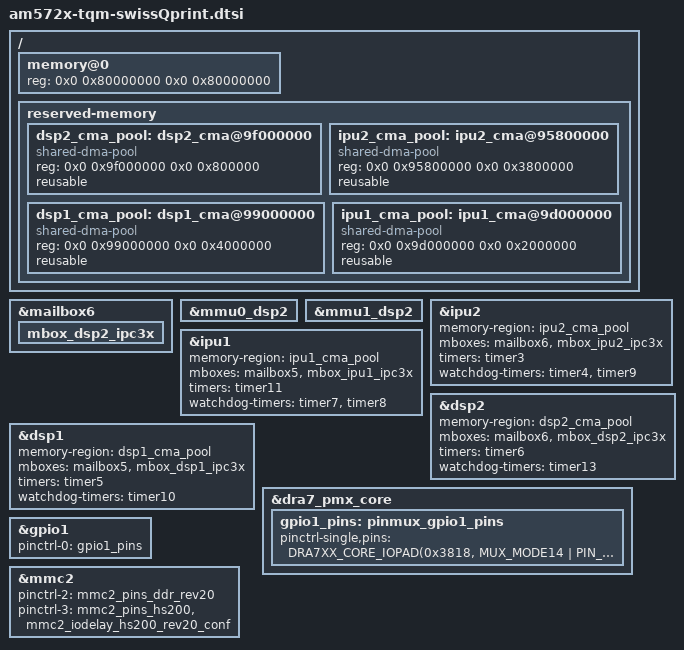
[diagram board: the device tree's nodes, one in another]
/*
 * Copyright (C) 2017 TQ Systems
 *
 * Author: Stefan Lange <s.lange@gateware.de>
 *
 * This program is free software; you can redistribute it and/or modify
 * it under the terms of the GNU General Public License version 2 as
 * published by the Free Software Foundation.
 */

#include "dra74x.dtsi"
#include "dra74x-mmc-iodelay.dtsi"
#include <dt-bindings/gpio/gpio.h>
#include <dt-bindings/interrupt-controller/irq.h>
#include "am57xx-tqm-swissQprint.dtsi"
#include "dra74-ipu-dsp-common.dtsi"

/ {
	memory@0 {
		device_type = "memory";
		reg = <0x0 0x80000000 0x0 0x80000000>;
	};

	reserved-memory {
		#address-cells = <2>;
		#size-cells = <2>;
		ranges;
		
		dsp2_cma_pool: dsp2_cma@9f000000 {
			compatible = "shared-dma-pool";
			reg = <0x0 0x9f000000 0x0 0x800000>;
			reusable;
			status = "okay";
		};

		ipu2_cma_pool: ipu2_cma@95800000 {
			compatible = "shared-dma-pool";
			reg = <0x0 0x95800000 0x0 0x3800000>;
			reusable;
			status = "okay";
		};

		dsp1_cma_pool: dsp1_cma@99000000 {
			compatible = "shared-dma-pool";
			reg = <0x0 0x99000000 0x0 0x4000000>;
			reusable;
			status = "okay";
		};

		ipu1_cma_pool: ipu1_cma@9d000000 {
			compatible = "shared-dma-pool";
			reg = <0x0 0x9d000000 0x0 0x2000000>;
			reusable;
			status = "okay";
		};
	};


};

&mailbox6 {
	mbox_dsp2_ipc3x: mbox_dsp2_ipc3x {
		status = "okay";
	};
};

&mmu0_dsp2 {
	status = "okay";
};

&mmu1_dsp2 {
	status = "okay";
};

&ipu2 {
	status = "okay";
	memory-region = <&ipu2_cma_pool>;
	mboxes = <&mailbox6 &mbox_ipu2_ipc3x>;
	timers = <&timer3>;
	watchdog-timers = <&timer4>, <&timer9>;
};

&ipu1 {
	status = "okay";
	memory-region = <&ipu1_cma_pool>;
	mboxes = <&mailbox5 &mbox_ipu1_ipc3x>;
	timers = <&timer11>;
	watchdog-timers = <&timer7>, <&timer8>;
};

&dsp2 {
	status = "okay";
	memory-region = <&dsp2_cma_pool>;
	mboxes = <&mailbox6 &mbox_dsp2_ipc3x>;
	timers = <&timer6>;
	watchdog-timers = <&timer13>;
};

&dsp1 {
	status = "okay";
	memory-region = <&dsp1_cma_pool>;
	mboxes = <&mailbox5 &mbox_dsp1_ipc3x>;
	timers = <&timer5>;
	watchdog-timers = <&timer10>;
};

&dra7_pmx_core {
	gpio1_pins: pinmux_gpio1_pins {
		pinctrl-single,pins = <
			DRA7XX_CORE_IOPAD(0x3818, MUX_MODE14 | PIN_INPUT | WAKEUP_EN) /* wakeup0.gpio1_0 */
		>;
	};
};

&gpio1 {
	pinctrl-names = "default";
	pinctrl-0 = <&gpio1_pins>;
};

&mmc2 {
	pinctrl-2 = <&mmc2_pins_ddr_rev20>;
	pinctrl-3 = <&mmc2_pins_hs200 &mmc2_iodelay_hs200_rev20_conf>;
};
